# iostm8af61a8 register map
Registers from a debugger description file.
Registers are 8-bit, access not given, no defined reset value unless marked. A register's access mark holds for its fields unless they carry their own. Addresses are absolute; registers are grouped by the start of their names; lines under a group give offsets from that group; [hi:lo] are bit positions; {n}, {i} and the like mark numbered series; 'fields as' and 'values as' point back to an identical list; <NAME> marks a mode.

## PA
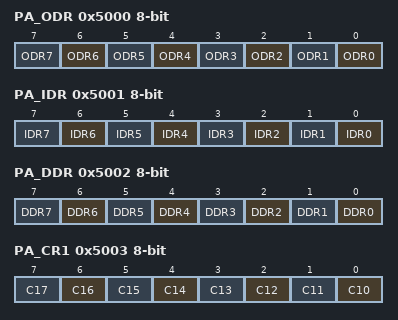
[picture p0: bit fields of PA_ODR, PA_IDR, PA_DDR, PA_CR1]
0x5000 PA_ODR — Port A data output latch register
  [n] ODR{n} (n=0..7)
0x5001 PA_IDR ro — Port A input pin value register
  [n] IDR{n} (n=0..7)
0x5002 PA_DDR — Port A data direction register
  [n] DDR{n} (n=0..7)
0x5003 PA_CR1 — Port A control register 1
  [n-10] C{n} (n=10..17)
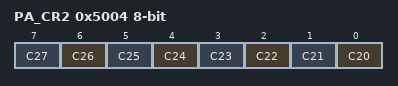
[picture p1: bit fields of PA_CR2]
0x5004 PA_CR2 — Port A control register 2
  [n-20] C{n} (n=20..27)

## PB
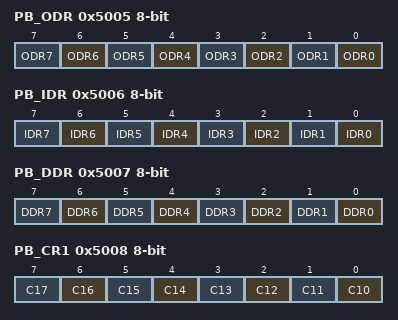
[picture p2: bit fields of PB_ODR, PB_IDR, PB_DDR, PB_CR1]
0x5005 PB_ODR — Port B data output latch register
  [n] ODR{n} (n=0..7)
0x5006 PB_IDR ro — Port B input pin value register
  [n] IDR{n} (n=0..7)
0x5007 PB_DDR — Port B data direction register
  [n] DDR{n} (n=0..7)
0x5008 PB_CR1 — Port B control register 1
  [n-10] C{n} (n=10..17)
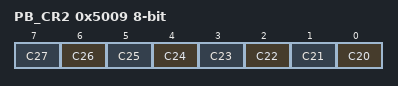
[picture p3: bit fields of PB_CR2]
0x5009 PB_CR2 — Port B control register 2
  [n-20] C{n} (n=20..27)

## PC
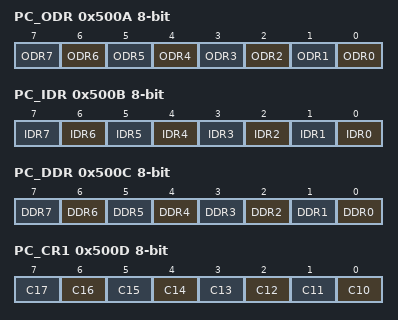
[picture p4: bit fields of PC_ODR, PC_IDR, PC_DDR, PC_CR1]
0x500A PC_ODR — Port C data output latch register
  [n] ODR{n} (n=0..7)
0x500B PC_IDR ro — Port C input pin value register
  [n] IDR{n} (n=0..7)
0x500C PC_DDR — Port C data direction register
  [n] DDR{n} (n=0..7)
0x500D PC_CR1 — Port C control register 1
  [n-10] C{n} (n=10..17)
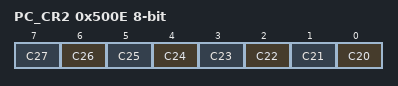
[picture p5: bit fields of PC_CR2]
0x500E PC_CR2 — Port C control register 2
  [n-20] C{n} (n=20..27)

## PD
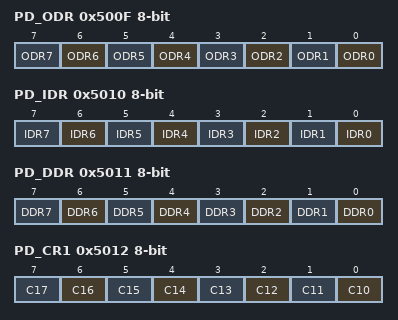
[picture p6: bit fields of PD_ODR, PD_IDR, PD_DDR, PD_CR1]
0x500F PD_ODR — Port D data output latch register
  [n] ODR{n} (n=0..7)
0x5010 PD_IDR ro — Port D input pin value register
  [n] IDR{n} (n=0..7)
0x5011 PD_DDR — Port D data direction register
  [n] DDR{n} (n=0..7)
0x5012 PD_CR1 — Port D control register 1
  [n-10] C{n} (n=10..17)
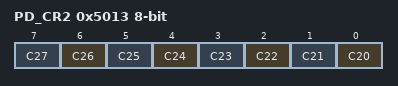
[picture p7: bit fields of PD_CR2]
0x5013 PD_CR2 — Port D control register 2
  [n-20] C{n} (n=20..27)

## PE
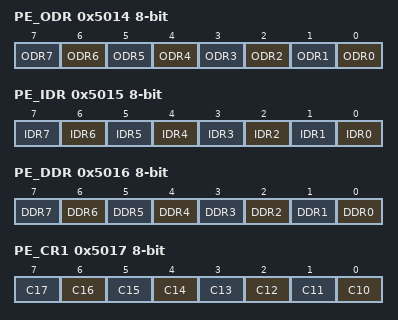
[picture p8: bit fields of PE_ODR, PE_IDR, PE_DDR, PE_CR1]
0x5014 PE_ODR — Port E data output latch register
  [n] ODR{n} (n=0..7)
0x5015 PE_IDR ro — Port E input pin value register
  [n] IDR{n} (n=0..7)
0x5016 PE_DDR — Port E data direction register
  [n] DDR{n} (n=0..7)
0x5017 PE_CR1 — Port E control register 1
  [n-10] C{n} (n=10..17)
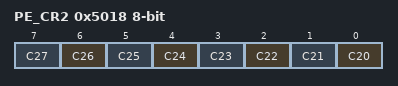
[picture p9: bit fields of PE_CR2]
0x5018 PE_CR2 — Port E control register 2
  [n-20] C{n} (n=20..27)

## PG
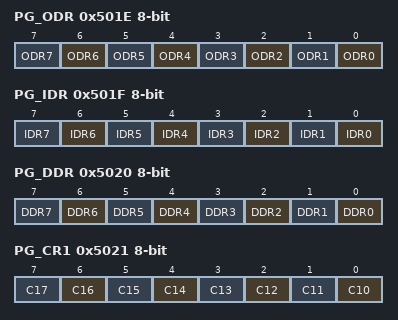
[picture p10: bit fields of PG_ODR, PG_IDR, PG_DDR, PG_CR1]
0x501E PG_ODR — Port G data output latch register
  [n] ODR{n} (n=0..7)
0x501F PG_IDR ro — Port G input pin value register
  [n] IDR{n} (n=0..7)
0x5020 PG_DDR — Port G data direction register
  [n] DDR{n} (n=0..7)
0x5021 PG_CR1 — Port G control register 1
  [n-10] C{n} (n=10..17)
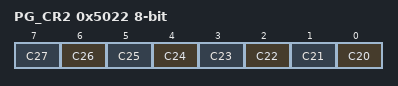
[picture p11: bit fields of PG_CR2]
0x5022 PG_CR2 — Port G control register 2
  [n-20] C{n} (n=20..27)

## FLASH
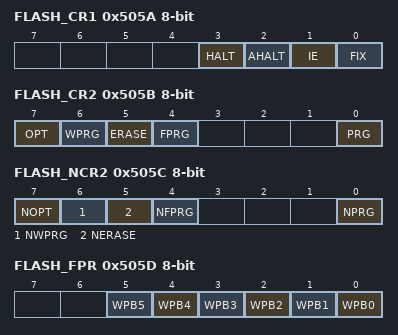
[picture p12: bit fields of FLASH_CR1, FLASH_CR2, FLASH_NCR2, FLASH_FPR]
0x505A FLASH_CR1 — Flash control register 1
  [3] HALT, [2] AHALT, [1] IE, [0] FIX
0x505B FLASH_CR2 — Flash control register 2
  [7] OPT, [6] WPRG, [5] ERASE, [4] FPRG, [0] PRG
0x505C FLASH_NCR2 — Flash complementary control register 2
  [7] NOPT, [6] NWPRG, [5] NERASE, [4] NFPRG, [0] NPRG
0x505D FLASH_FPR ro — Flash protection register
  [n] WPB{n} (n=0..5)
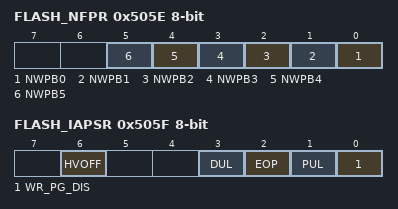
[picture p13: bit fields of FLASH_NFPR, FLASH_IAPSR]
0x505E FLASH_NFPR ro — Flash complementary protection register
  [n] NWPB{n} (n=0..5)
0x505F FLASH_IAPSR — Flash in-application programming status register
  [6] HVOFF ro, [3] DUL, [2] EOP ro, [1] PUL, [0] WR_PG_DIS ro
0x5062 FLASH_PUKR — Flash program memory unprotection register
  [7:0] PUK
0x5064 FLASH_DUKR — Data EEPROM unprotection register
  [7:0] DUK

## EXTI
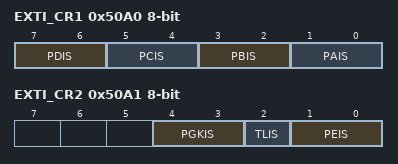
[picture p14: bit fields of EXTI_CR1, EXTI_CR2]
0x50A0 EXTI_CR1 — External interrupt control register 1
  [7:6] PDIS, [5:4] PCIS, [3:2] PBIS, [1:0] PAIS
0x50A1 EXTI_CR2 — External interrupt control register 2
  [4:3] PGKIS, [2] TLIS, [1:0] PEIS

## Notices in the file
Copyright 2017 IAR Systems AB.
